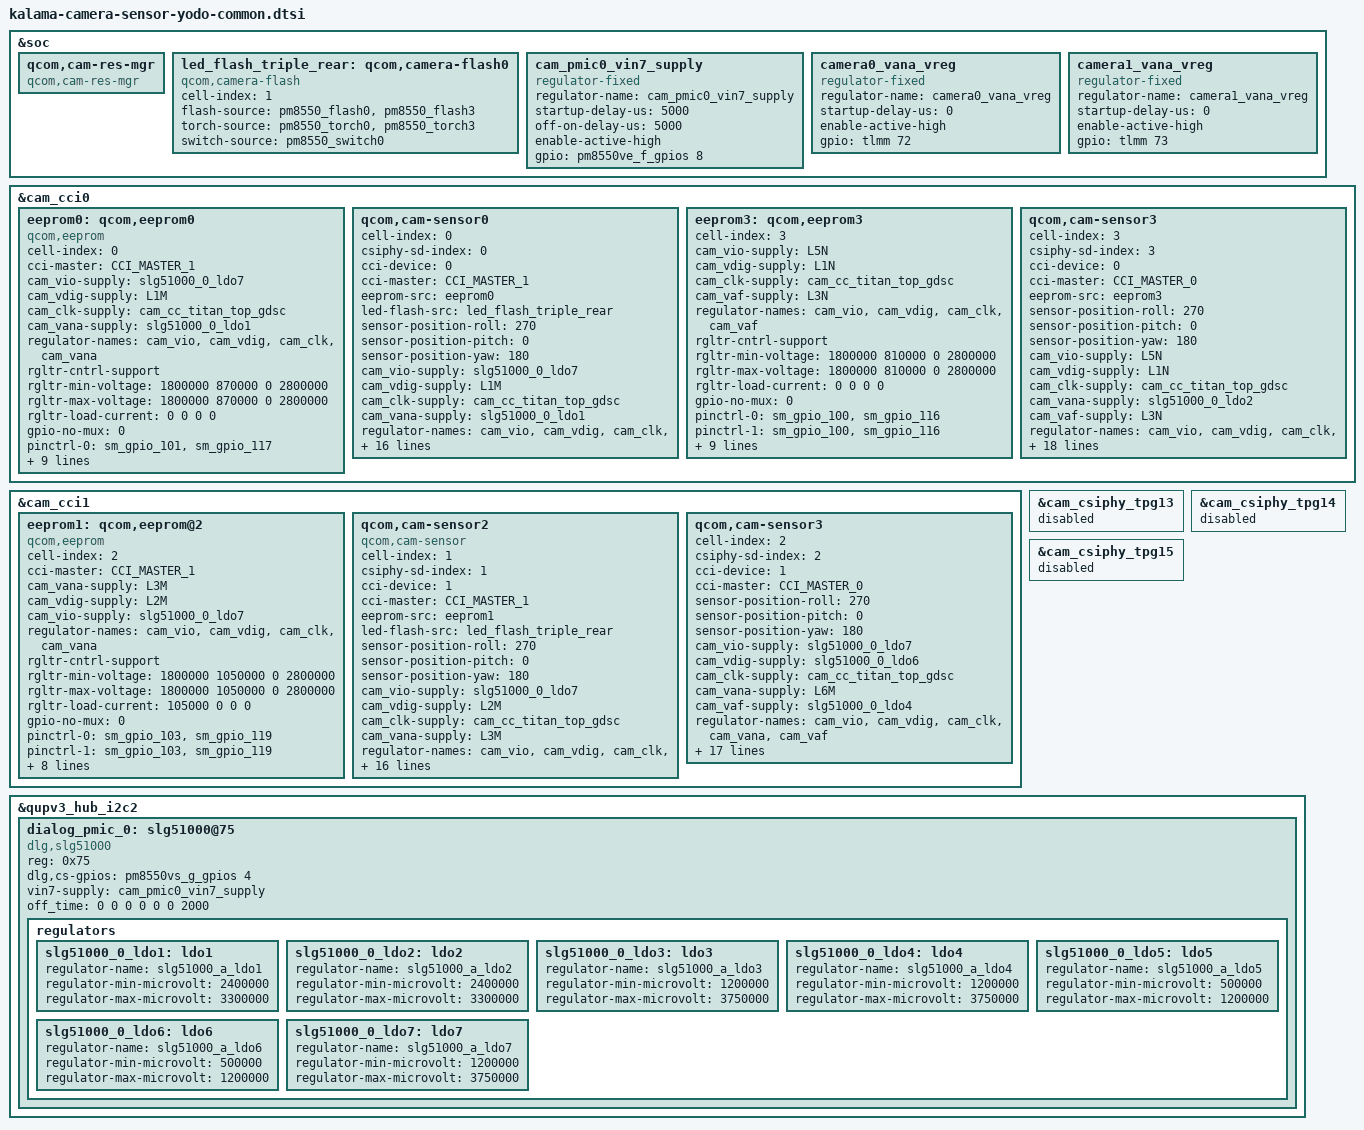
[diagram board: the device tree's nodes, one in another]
#include <dt-bindings/clock/qcom,camcc-kalama.h>
#include <dt-bindings/msm/msm-camera.h>

&soc {
	qcom,cam-res-mgr {
		compatible = "qcom,cam-res-mgr";
		status = "ok";
	};

	led_flash_triple_rear: qcom,camera-flash0 {
		cell-index = <1>;
		compatible = "qcom,camera-flash";
		flash-source = <&pm8550_flash0 &pm8550_flash3>;
		torch-source = <&pm8550_torch0 &pm8550_torch3>;
		switch-source = <&pm8550_switch0>;
		status = "ok";
	};

	cam_pmic0_vin7_supply: cam_pmic0_vin7_supply {
		compatible = "regulator-fixed";
		regulator-name = "cam_pmic0_vin7_supply";
		startup-delay-us = <5000>;
		off-on-delay-us = <5000>;
		enable-active-high;
		gpio = <&pm8550ve_f_gpios 8 0>;
	};

	camera0_vana_vreg: camera0_vana_vreg {
		compatible = "regulator-fixed";
		regulator-name = "camera0_vana_vreg";
		startup-delay-us = <0>;
		enable-active-high;
		gpio = <&tlmm 72 0>;
	};

	camera1_vana_vreg: camera1_vana_vreg {
		compatible = "regulator-fixed";
		regulator-name = "camera1_vana_vreg";
		startup-delay-us = <0>;
		enable-active-high;
		gpio = <&tlmm 73 0>;
	};
};

&cam_cci0 {
	#address-cells = <1>;
	#size-cells = <0>;

	eeprom0: qcom,eeprom0 {
		cell-index = <0>;
		compatible = "qcom,eeprom";
		cci-master = <CCI_MASTER_1>;
		cam_vio-supply = <&slg51000_0_ldo7>;
		cam_vdig-supply = <&L1M>;
		cam_clk-supply = <&cam_cc_titan_top_gdsc>;
		cam_vana-supply = <&slg51000_0_ldo1>;
		regulator-names = "cam_vio", "cam_vdig", "cam_clk", "cam_vana";
		rgltr-cntrl-support;
		rgltr-min-voltage = <1800000 870000 0 2800000>;
		rgltr-max-voltage = <1800000 870000 0 2800000>;
		rgltr-load-current = <0 0 0 0>;
		gpio-no-mux = <0>;
		pinctrl-names = "cam_default", "cam_suspend";
		pinctrl-0 = <&sm_gpio_101 &sm_gpio_117>;
		pinctrl-1 = <&sm_gpio_101 &sm_gpio_117>;
		gpios = <&tlmm 101 0>, <&tlmm 117 0>;
		gpio-reset = <1>;
		gpio-req-tbl-num = <0 1>;
		gpio-req-tbl-flags = <1 0>;
		gpio-req-tbl-label = "CAMIF_MCLK1", "CAM_RESET1";
		clocks = <&camcc CAM_CC_MCLK1_CLK>;
		clock-names = "cam_clk";
		clock-cntl-level = "nominal";
		clock-rates = <24000000>;
		status = "ok";
	};

	// imx888 cell-index 0. probed. no eeprom read.
	qcom,cam-sensor0 {
		cell-index = <0>;
		//compatible = "qcom,cam-sensor";
		csiphy-sd-index = <0>;
		cci-device = <0>;
		cci-master = <CCI_MASTER_1>;
		eeprom-src = <&eeprom0>;
		led-flash-src = <&led_flash_triple_rear>;
		sensor-position-roll = <270>;
		sensor-position-pitch = <0>;
		sensor-position-yaw = <180>;
		cam_vio-supply = <&slg51000_0_ldo7>;
		cam_vdig-supply = <&L1M>;
		cam_clk-supply = <&cam_cc_titan_top_gdsc>;
		cam_vana-supply = <&slg51000_0_ldo1>;
		regulator-names = "cam_vio", "cam_vdig", "cam_clk", "cam_vana";
		rgltr-cntrl-support;
		rgltr-min-voltage = <1800000 870000 0 0>;
		rgltr-max-voltage = <1800000 870000 0 0>;
		rgltr-load-current = <105000 0 0 0>;
		gpio-no-mux = <0>;
		pinctrl-names = "cam_default", "cam_suspend";
		pinctrl-0 = <&sm_gpio_101 &sm_gpio_117>;
		pinctrl-1 = <&sm_gpio_101 &sm_gpio_117>;
		gpios = <&tlmm 101 0>, <&tlmm 117 0>;
		gpio-reset = <1>;
		gpio-req-tbl-num = <0 1>;
		gpio-req-tbl-flags = <1 0>;
		gpio-req-tbl-label = "CAMIF_MCLK1", "CAM_RESET1";
		clocks = <&camcc CAM_CC_MCLK1_CLK>;
		clock-names = "cam_clk";
		clock-cntl-level = "nominal";
		clock-rates = <24000000>;
		status = "ok";
	};

	eeprom3: qcom,eeprom3 {
		cell-index = <3>;
		//cell-index = <1>;
		//compatible = "qcom,eeprom";
		cam_vio-supply = <&L5N>;
		cam_vdig-supply = <&L1N>;
		cam_clk-supply = <&cam_cc_titan_top_gdsc>;
		cam_vaf-supply = <&L3N>;
		regulator-names = "cam_vio", "cam_vdig", "cam_clk", "cam_vaf";
		rgltr-cntrl-support;
		rgltr-min-voltage = <1800000 810000 0 2800000>;
		rgltr-max-voltage = <1800000 810000 0 2800000>;
		rgltr-load-current = <0 0 0 0>;
		gpio-no-mux = <0>;
		pinctrl-names = "cam_default", "cam_suspend";
		pinctrl-0 = <&sm_gpio_100 &sm_gpio_116>;
		pinctrl-1 = <&sm_gpio_100 &sm_gpio_116>;
		gpios = <&tlmm 100 0>, <&tlmm 116 0>;
		gpio-reset = <1>;
		gpio-req-tbl-num = <0 1>;
		gpio-req-tbl-flags = <1 0>;
		gpio-req-tbl-label = "CAMIF_MCLK0", "CAM_RESET0";
		cci-master = <CCI_MASTER_0>;
		clocks = <&camcc CAM_CC_MCLK0_CLK>;
		clock-names = "cam_clk";
		clock-cntl-level = "nominal";
		clock-rates = <24000000>;
		status = "ok";
	};

	// imx650. cell-index 3(why?). no probe
	qcom,cam-sensor3 {
		cell-index = <3>;
		//cell-index = <1>;
		//compatible = "qcom,cam-sensor";
		csiphy-sd-index = <3>;
		cci-device = <0>;
		cci-master = <CCI_MASTER_0>;
		eeprom-src = <&eeprom3>;
		//led-flash-src = <&led_flash_triple_rear>;
		sensor-position-roll = <270>;
		sensor-position-pitch = <0>;
		sensor-position-yaw = <180>;
		cam_vio-supply = <&L5N>;
		cam_vdig-supply = <&L1N>;
		cam_clk-supply = <&cam_cc_titan_top_gdsc>;
		cam_vana-supply = <&slg51000_0_ldo2>;
		cam_vaf-supply = <&L3N>;
		regulator-names = "cam_vio", "cam_vdig", "cam_clk", "cam_vana", "cam_vaf";
		rgltr-cntrl-support;
		rgltr-min-voltage = <1860000 810000 0 2800000 2800000>;
		rgltr-max-voltage = <1860000 810000 0 2800000 2800000>;
		rgltr-load-current = <0 0 0 0 0>;
		gpio-no-mux = <0>;
		pinctrl-names = "cam_default", "cam_suspend";
		pinctrl-0 = <&sm_gpio_100 &sm_gpio_116>;
		pinctrl-1 = <&sm_gpio_100 &sm_gpio_116>;
		gpios = <&tlmm 100 0>, <&tlmm 116 0>;
		gpio-reset = <1>;
		gpio-req-tbl-num = <0 1>;
		gpio-req-tbl-flags = <1 0>;
		gpio-req-tbl-label = "CAMIF_MCLK0", "CAM_RESET0";
		clocks = <&camcc CAM_CC_MCLK0_CLK>;
		clock-names = "cam_clk";
		clock-cntl-level = "nominal";
		clock-rates = <24000000>;
		status = "ok";
	};
};

&cam_cci1 {
	eeprom1: qcom,eeprom@2 {
		cell-index = <2>;
		compatible = "qcom,eeprom";
		cci-master = <CCI_MASTER_1>;
		cam_vana-supply = <&L3M>;
		cam_vdig-supply = <&L2M>;
		cam_vio-supply = <&slg51000_0_ldo7>;
		regulator-names = "cam_vio", "cam_vdig", "cam_clk", "cam_vana";
		rgltr-cntrl-support;
		rgltr-min-voltage = <1800000 1050000 0 2800000>;
		rgltr-max-voltage = <1800000 1050000 0 2800000>;
		rgltr-load-current = <105000 0 0 0>;
		gpio-no-mux = <0>;
		pinctrl-names = "cam_default", "cam_suspend";
		pinctrl-0 = <&sm_gpio_103 &sm_gpio_119>;
		pinctrl-1 = <&sm_gpio_103 &sm_gpio_119>;
		gpios = <&tlmm 103 0>, <&tlmm 119 0>;
		gpio-reset = <1>;
		gpio-req-tbl-num = <0 1>;
		gpio-req-tbl-flags = <1 0>;
		gpio-req-tbl-label = "CAMIF_MCLK3", "CAM_RESET3";
		clocks = <&camcc CAM_CC_MCLK3_CLK>;
		clock-names = "cam_clk";
		clock-cntl-level = "nominal";
		clock-rates = <24000000>;
		status = "ok";
	};

	// imx663. good cell-index. probed. eeprom good
	qcom,cam-sensor2 {
		cell-index = <1>;
		compatible = "qcom,cam-sensor";
		csiphy-sd-index = <1>;
		cci-device = <1>;
		cci-master = <CCI_MASTER_1>;
		eeprom-src = <&eeprom1>;
		led-flash-src = <&led_flash_triple_rear>;
		sensor-position-roll = <270>;
		sensor-position-pitch = <0>;
		sensor-position-yaw = <180>;
		cam_vio-supply = <&slg51000_0_ldo7>;
		cam_vdig-supply = <&L2M>;
		cam_clk-supply = <&cam_cc_titan_top_gdsc>;
		cam_vana-supply = <&L3M>;
		regulator-names = "cam_vio", "cam_vdig", "cam_clk", "cam_vana";
		rgltr-cntrl-support;
		rgltr-min-voltage = <1800000 1050000 0 2800000>;
		rgltr-max-voltage = <1800000 1050000 0 2800000>;
		rgltr-load-current = <105000 0 0 0>;
		gpio-no-mux = <0>;
		pinctrl-names = "cam_default", "cam_suspend";
		pinctrl-0 = <&sm_gpio_103 &sm_gpio_119>;
		pinctrl-1 = <&sm_gpio_103 &sm_gpio_119>;
		gpios = <&tlmm 103 0>, <&tlmm 119 0>;
		gpio-reset = <1>;
		gpio-req-tbl-num = <0 1>;
		gpio-req-tbl-flags = <1 0>;
		gpio-req-tbl-label = "CAMIF_MCLK3", "CAM_RESET3";
		clocks = <&camcc CAM_CC_MCLK3_CLK>;
		clock-names = "cam_clk";
		clock-cntl-level = "nominal";
		clock-rates = <24000000>;
		status = "ok";
	};

	// imx563. good cell-index. no probe
	qcom,cam-sensor3 {
		cell-index = <2>;
		//cell-index = <1>;
		//compatible = "qcom,cam-sensor";
		csiphy-sd-index = <2>;
		cci-device = <1>;
		cci-master = <CCI_MASTER_0>;
		//eeprom-src = <&eeprom0>;
		//led-flash-src = <&led_flash_triple_rear>;
		sensor-position-roll = <270>;
		sensor-position-pitch = <0>;
		sensor-position-yaw = <180>;
		cam_vio-supply = <&slg51000_0_ldo7>;
		cam_vdig-supply = <&slg51000_0_ldo6>;
		cam_clk-supply = <&cam_cc_titan_top_gdsc>;
		cam_vana-supply = <&L6M>;
		cam_vaf-supply = <&slg51000_0_ldo4>;
		regulator-names = "cam_vio", "cam_vdig", "cam_clk", "cam_vana", "cam_vaf";
		rgltr-cntrl-support;
		rgltr-min-voltage = <1800000 1100000 0 2800000 2800000>;
		rgltr-max-voltage = <1800000 1100000 0 2800000 2800000>;
		rgltr-load-current = <105000 0 0 0 0>;
		gpio-no-mux = <0>;
		pinctrl-names = "cam_default", "cam_suspend";
		pinctrl-0 = <&sm_gpio_102 &sm_gpio_118>;
		pinctrl-1 = <&sm_gpio_102 &sm_gpio_118>;
		gpios = <&tlmm 102 0>, <&tlmm 118 0>;
		gpio-reset = <1>;
		gpio-req-tbl-num = <0 1>;
		gpio-req-tbl-flags = <1 0>;
		gpio-req-tbl-label = "CAMIF_MCLK2", "CAM_RESET2";
		clocks = <&camcc CAM_CC_MCLK2_CLK>;
		clock-names = "cam_clk";
		clock-cntl-level = "nominal";
		clock-rates = <24000000>;
		status = "ok";
	};
};

&cam_csiphy_tpg13 {
	status = "disabled";
};

&cam_csiphy_tpg14 {
	status = "disabled";
};

&cam_csiphy_tpg15 {
	status = "disabled";
};

&qupv3_hub_i2c2 {
	dialog_pmic_0: slg51000@75 {
		compatible = "dlg,slg51000";
		reg = <0x75>;
		dlg,cs-gpios = <&pm8550vs_g_gpios 4 0>;
		vin7-supply = <&cam_pmic0_vin7_supply>;
		off_time = <0 0 0 0 0 0 2000>;
		status = "ok";

		regulators {
			slg51000_0_ldo1: ldo1 {
				regulator-name = "slg51000_a_ldo1";
				regulator-min-microvolt = <2400000>;
				regulator-max-microvolt = <3300000>;
			};

			slg51000_0_ldo2: ldo2 {
				regulator-name = "slg51000_a_ldo2";
				regulator-min-microvolt = <2400000>;
				regulator-max-microvolt = <3300000>;
			};

			slg51000_0_ldo3: ldo3 {
				regulator-name = "slg51000_a_ldo3";
				regulator-min-microvolt = <1200000>;
				regulator-max-microvolt = <3750000>;
			};

			slg51000_0_ldo4: ldo4 {
				regulator-name = "slg51000_a_ldo4";
				regulator-min-microvolt = <1200000>;
				regulator-max-microvolt = <3750000>;
			};

			slg51000_0_ldo5: ldo5 {
				regulator-name = "slg51000_a_ldo5";
				regulator-min-microvolt = <500000>;
				regulator-max-microvolt = <1200000>;
			};

			slg51000_0_ldo6: ldo6 {
				regulator-name = "slg51000_a_ldo6";
				regulator-min-microvolt = <500000>;
				regulator-max-microvolt = <1200000>;
			};

			slg51000_0_ldo7: ldo7 {
				regulator-name = "slg51000_a_ldo7";
				regulator-min-microvolt = <1200000>;
				regulator-max-microvolt = <3750000>;
			};
		};
	};
};
